# PCIE_CAP_EXT_REGS register map
Vendor: Texas Instruments
Peripheral module from a debugger description file (folder 66AK2G0x_66AK2G1x).
Registers are 32-bit, read-only, reset 0x0 unless marked. A register's access mark holds for its fields unless they carry their own. Offsets are as the file gives them; lines under a group give offsets from that group; [hi:lo] are bit positions; {n}, {i} and the like mark numbered series; 'fields as' and 'values as' point back to an identical list; <NAME> marks a mode.

## PCIE_CAP_EXT_REGS
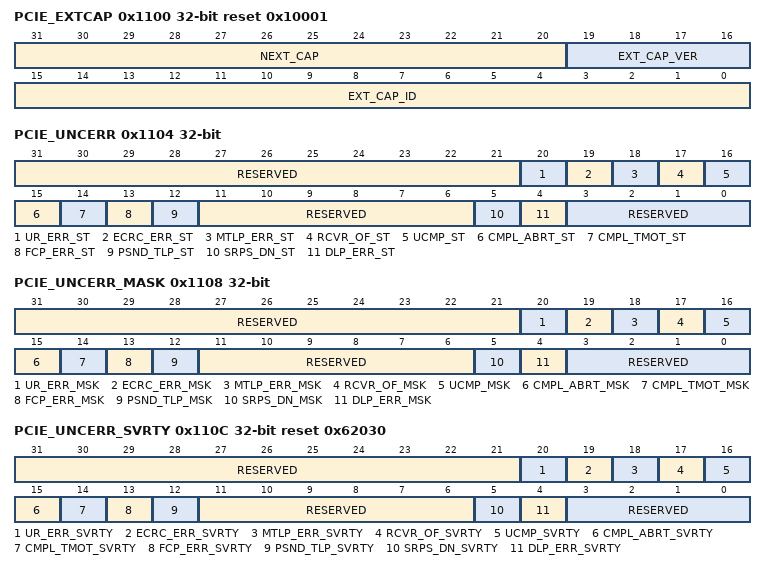
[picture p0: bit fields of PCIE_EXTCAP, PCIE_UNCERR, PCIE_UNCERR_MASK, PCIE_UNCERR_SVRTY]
0x1100 PCIE_EXTCAP reset 0x10001
  [31:20] NEXT_CAP — Next Capability Pointer
  [19:16] EXT_CAP_VER — Extended Capability Version
  [15:0] EXT_CAP_ID — PCIe Extended Capability ID
0x1104 PCIE_UNCERR access not given
  [31:21] RESERVED ro — Reads return 0 and writes have no effect.
  [20] UR_ERR_ST — Unsupported Request Error Status (access RW1C)
  [19] ECRC_ERR_ST — ECRC Error Status (access RW1C)
  [18] MTLP_ERR_ST — Malformed TLP Status (access RW1C)
  [17] RCVR_OF_ST — Receiver Overflow Status (access RW1C)
  [16] UCMP_ST — Unexpected Completion Status (access RW1C)
  [15] CMPL_ABRT_ST — Completer Abort Status (access RW1C)
  [14] CMPL_TMOT_ST — Completion Timeout Status (access RW1C)
  [13] FCP_ERR_ST — Flow Control Protocol Error Status (access RW1C)
  [12] PSND_TLP_ST — Poisoned TLP Status (access RW1C)
  [11:6] RESERVED ro — Reads return 0 and writes have no effect.
  [5] SRPS_DN_ST ro — Surprise Down Error Status. Not supported.
  [4] DLP_ERR_ST — Data Link Protocol Error Status (access RW1C)
  [3:0] RESERVED ro — Reads return 0 and writes have no effect.
0x1108 PCIE_UNCERR_MASK access per field
  [31:21] RESERVED ro — Reads return 0 and writes have no effect.
  [20] UR_ERR_MSK rw — Unsupported Request Error Mask
  [19] ECRC_ERR_MSK rw — ECRC Error Mask
  [18] MTLP_ERR_MSK rw — Malformed TLP Mask
  [17] RCVR_OF_MSK rw — Receiver Overflow Mask
  [16] UCMP_MSK rw — Unexpected Completion Mask
  [15] CMPL_ABRT_MSK rw — Completer Abort Mask
  [14] CMPL_TMOT_MSK rw — Completion Timeout Mask
  [13] FCP_ERR_MSK rw — Flow Control Protocol Error Mask
  [12] PSND_TLP_MSK rw — Poisoned TLP Mask
  [11:6] RESERVED ro — Reads return 0 and writes have no effect.
  [5] SRPS_DN_MSK ro — Surprise Down Error Mask. Not supported.
  [4] DLP_ERR_MSK rw — Data Link Protocol Error Mask
  [3:0] RESERVED ro — Reads return 0 and writes have no effect.
0x110C PCIE_UNCERR_SVRTY access per field reset 0x62030
  [31:21] RESERVED ro — Reads return 0 and writes have no effect.
  [20] UR_ERR_SVRTY rw — Unsupported Request Error Severity
  [19] ECRC_ERR_SVRTY rw — ECRC Error Severity
  [18] MTLP_ERR_SVRTY rw — Malformed TLP Severity
  [17] RCVR_OF_SVRTY rw — Receiver Overflow Severity
  [16] UCMP_SVRTY rw — Unexpected Completion Severity
  [15] CMPL_ABRT_SVRTY rw — Completer Abort Severity
  [14] CMPL_TMOT_SVRTY rw — Completion Timeout Severity
  [13] FCP_ERR_SVRTY rw — Flow Control Protocol Error Severity
  [12] PSND_TLP_SVRTY rw — Poisoned TLP Severity
  [11:6] RESERVED ro — Reads return 0 and writes have no effect.
  [5] SRPS_DN_SVRTY ro — Surprise Down Error Severity. Not supported.
  [4] DLP_ERR_SVRTY rw — Data Link Protocol Error Severity
  [3:0] RESERVED ro — Reads return 0 and writes have no effect.
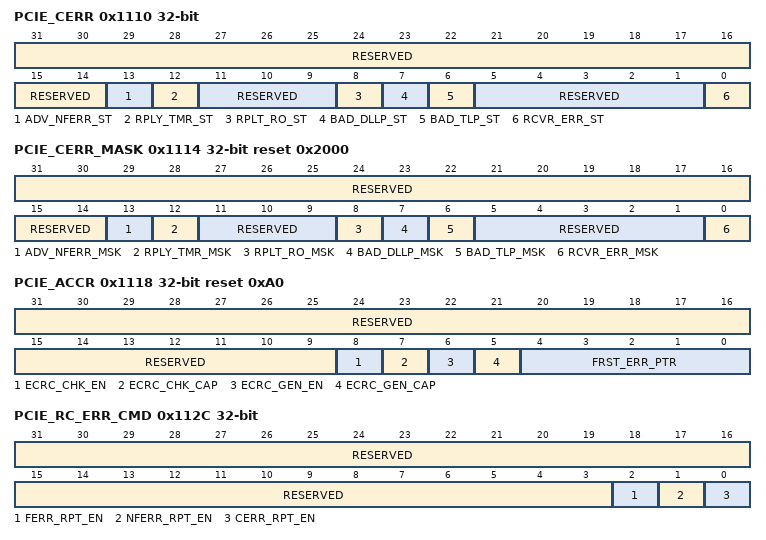
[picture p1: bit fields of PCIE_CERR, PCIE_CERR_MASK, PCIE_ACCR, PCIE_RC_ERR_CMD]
0x1110 PCIE_CERR access not given
  [31:14] RESERVED ro — Reads return 0 and writes have no effect.
  [13] ADV_NFERR_ST — Advisory Non-Fatal Error Status (access RW1C)
  [12] RPLY_TMR_ST — Replay Timer Timeout Status (access RW1C)
  [11:9] RESERVED ro — Reads return 0 and writes have no effect.
  [8] RPLT_RO_ST — REPLAY_NUM Rollover Status (access RW1C)
  [7] BAD_DLLP_ST — Bad DLLP Status (access RW1C)
  [6] BAD_TLP_ST — Bad TLP Status (access RW1C)
  [5:1] RESERVED ro — Reads return 0 and writes have no effect.
  [0] RCVR_ERR_ST — Receiver Error Status (access RW1C)
0x1114 PCIE_CERR_MASK access per field reset 0x2000
  [31:14] RESERVED ro — Reads return 0 and writes have no effect.
  [13] ADV_NFERR_MSK rw — Advisory Non Fatal Error MaskThis bit is Set by default to enable compatibility with software that does not comprehend Role-Based Error Reporting.
  [12] RPLY_TMR_MSK rw — Reply Timer Timeout Mask
  [11:9] RESERVED ro — Reads return 0 and writes have no effect.
  [8] RPLT_RO_MSK rw — REPLAY_NUM Rollover Mask
  [7] BAD_DLLP_MSK rw — Bad DLLP Mask
  [6] BAD_TLP_MSK rw — Bad TLP Mask
  [5:1] RESERVED ro — Reads return 0 and writes have no effect.
  [0] RCVR_ERR_MSK rw — Receiver Error Mask
0x1118 PCIE_ACCR access per field reset 0xA0
  [31:9] RESERVED ro — Reads return 0 and writes have no effect.
  [8] ECRC_CHK_EN rw — ECRC Check Enable
  [7] ECRC_CHK_CAP ro — ECRC Check Capable
  [6] ECRC_GEN_EN rw — ECRC Generation Enable
  [5] ECRC_GEN_CAP ro — ECRC Generation Capability
  [4:0] FRST_ERR_PTR ro — First Error PointerThe First Error Pointer is a field that identifies the bit position of the first error reported in the Uncorrectable Error Status register.
0x111C PCIE_HDR_LOG0
  [31:0] HDR_DW0 — First DWORD of Header for a detected error.
0x1120 PCIE_HDR_LOG1
  [31:0] HDR_DW1 — Second DWORD of header for a detected error.
0x1124 PCIE_HDR_LOG2
  [31:0] HDR_DW2 — Third DWORD of header for a detected error.
0x1128 PCIE_HDR_LOG3
  [31:0] HDR_DW3 — Fourth DWORD of Header for a detected error.
0x112C PCIE_RC_ERR_CMD access per field
  [31:3] RESERVED ro — Reads return 0 and writes have no effect.
  [2] FERR_RPT_EN rw — Fatal Error Reporting Enable.
  [1] NFERR_RPT_EN rw — Nonfatal Error Reporting Enable.
  [0] CERR_RPT_EN rw — Correctable Error Reporting Enable.
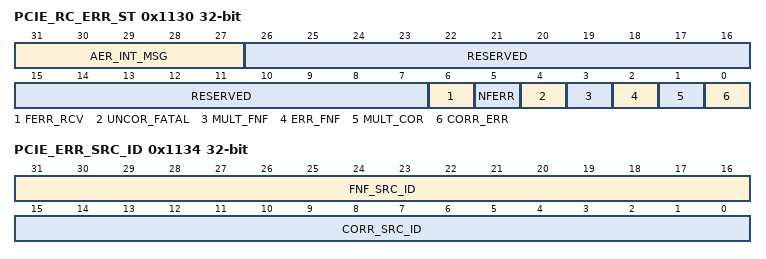
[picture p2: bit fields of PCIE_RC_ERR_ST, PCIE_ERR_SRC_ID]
0x1130 PCIE_RC_ERR_ST access not given
  [31:27] AER_INT_MSG ro — AER Interrupt Message Number. Writable through internal bus interface.
  [26:7] RESERVED ro — Reads return 0 and writes have no effect.
  [6] FERR_RCV ro — Fatal Error Messages Received.
  [5] NFERR — Non-Fatal Error Messages Received. (access RW1C)
  [4] UNCOR_FATAL — First Uncorrectable Fatal Received. (access RW1C)
  [3] MULT_FNF — Multiple Uncorrectable Error (ERR_FATAL/NONFATAL) Received. (access RW1C)
  [2] ERR_FNF — Uncorrectable Error (ERR_FATAL/NONFATAL) Received. (access RW1C)
  [1] MULT_COR — Multiple Correctable Error (ERR_COR) Received. (access RW1C)
  [0] CORR_ERR — Correctable Error (ERR_COR) Received. (access RW1C)
0x1134 PCIE_ERR_SRC_ID
  [31:16] FNF_SRC_ID — Fatal or Non-Fatal error source identification
  [15:0] CORR_SRC_ID — Correctable error source identification
